# LPC55S16 register map
Vendor: nxp.com; File version: 1.0
CPU: CM33 r2p0, little endian, MPU, FPU, VTOR, 3 interrupt priority bits
Registers are 32-bit, read-write, reset 0x0 unless marked. A register's access mark holds for its fields unless they carry their own. Offsets are from the block's base; [hi:lo] are bit positions; {n}, {i} and the like mark numbered series.

## SYSCTL — system controller
Base 0x40023000
0x00 UPDATELCKOUT — update lock out control
  [0] UPDATELCKOUT — All Registers
    0=NORMAL_MODE (Normal Mode. Can be written to.); 1=PROTECTED_MODE (Protected Mode. Cannot be written to.)
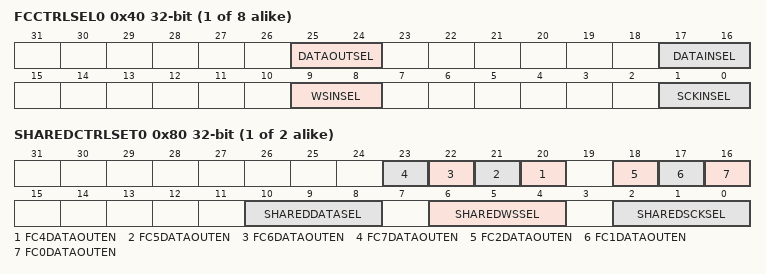
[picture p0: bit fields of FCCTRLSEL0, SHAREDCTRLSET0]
{0x40+4i} FCCTRLSEL{i} (i=0..7) — Selects the source for SCK going into Flexcomm index
  [25:24] DATAOUTSEL — Selects the source for DATA output from this Flexcomm.
    0=ORIG_FLEX_I2S_SIGNALS (Selects the dedicated FCn_RXD_SDA_MOSI_DATA output from this Flexcomm.); 1=SHARED_SET0_I2S_SIGNALS (Output data is taken from shared signal set 0 (defined by SHAREDCTRLSET0).); 2=SHARED_SET1_I2S_SIGNALS (Output data is taken from shared signal set 1 (defined by SHAREDCTRLSET1).)
  [17:16] DATAINSEL — Selects the source for DATA input to this Flexcomm.
    0=ORIG_FLEX_I2S_SIGNALS (Selects the dedicated FCn_RXD_SDA_MOSI_DATA input for this Flexcomm.); 1=SHARED_SET0_I2S_SIGNALS (Input data is taken from shared signal set 0 (defined by SHAREDCTRLSET0).); 2=SHARED_SET1_I2S_SIGNALS (Input data is taken from shared signal set 1 (defined by SHAREDCTRLSET1).)
  [9:8] WSINSEL — Selects the source for WS going into this Flexcomm.
    0=ORIG_FLEX_I2S_SIGNALS (Selects the dedicated (FCn_TXD_SCL_MISO_WS) function for this Flexcomm.); 1=SHARED_SET0_I2S_SIGNALS (WS is taken from shared signal set 0 (defined by SHAREDCTRLSET0).); 2=SHARED_SET1_I2S_SIGNALS (WS is taken from shared signal set 1 (defined by SHAREDCTRLSET1).)
  [1:0] SCKINSEL rw-once — Selects the source for SCK going into this Flexcomm.
    0=ORIG_FLEX_I2S_SIGNALS (Selects the dedicated FCn_SCK function for this Flexcomm.); 1=SHARED_SET0_I2S_SIGNALS (SCK is taken from shared signal set 0 (defined by SHAREDCTRLSET0).); 2=SHARED_SET1_I2S_SIGNALS (SCK is taken from shared signal set 1 (defined by SHAREDCTRLSET1).)
{0x80+4i} SHAREDCTRLSET{i} (i=0..1) — Selects sources and data combinations for shared signal set index.
  [n+16] FC{n}DATAOUTEN (n=4..7) — Controls FC{n} contribution to SHAREDDATAOUT for this shared set.
    0=INPUT (Data output from FC{n} does not contribute to this shared set.); 1=OUTPUT (Data output from FC{n} does contribute to this shared set.)
  [18] FC2DATAOUTEN — Controls FC2 contribution to SHAREDDATAOUT for this shared set.
    0=INPUT (Data output from FC2 does not contribute to this shared set.); 1=OUTPUT (Data output from FC2 does contribute to this shared set.)
  [17] FC1DATAOUTEN — Controls FC1 contribution to SHAREDDATAOUT for this shared set.
    0=INPUT (Data output from FC1 does not contribute to this shared set.); 1=OUTPUT (Data output from FC1 does contribute to this shared set.)
  [16] FC0DATAOUTEN — Controls FC0 contribution to SHAREDDATAOUT for this shared set.
    0=INPUT (Data output from FC0 does not contribute to this shared set.); 1=OUTPUT (Data output from FC0 does contribute to this shared set.)
  [10:8] SHAREDDATASEL — Selects the source for DATA input for this shared signal set.
    {v}=FLEXCOMM{v} (DATA input for this shared signal set comes from Flexcomm {v}.) (v=0..7)
  [6:4] SHAREDWSSEL — Selects the source for WS of this shared signal set.
    {v}=FLEXCOMM{v} (WS for this shared signal set comes from Flexcomm {v}.) (v=0..7)
  [2:0] SHAREDSCKSEL — Selects the source for SCK of this shared signal set.
    {v}=FLEXCOMM{v} (SCK for this shared signal set comes from Flexcomm {v}.) (v=0..7)
0x100 USB_HS_STATUS ro (reset mask 0x1C0FF00) — Status register for USB HS
  [0] USBHS_3V_NOK — USB_HS: Low voltage detection on 3.3V supply.
    0=SUPPLY_3V_OK (3v3 supply is good.); 1=SUPPLY_3V_LOW (3v3 supply is too low.)
0x180 CODE_GRAY_LSB — CODE_GRAY LSB input Register
  [31:0] CODE_GRAY_LSB — Gray code (42bits) to be converted back to binary
0x184 CODE_GRAY_MSB — CODE_GRAY MSB input Register
  [9:0] CODE_GRAY_MSB — Gray code (42bits) to be converted back to binary
0x188 CODE_BIN_LSB ro — CODE_BIN LSB output Register
  [31:0] CODE_BIN_LSB — Binary converted code (42bits)
0x18C CODE_BIN_MSB ro — CODE_BIN MSB output Register
  [9:0] CODE_BIN_MSB — Binary converted code (42bits)
